# SN32F240 register map
Vendor: SONiX Technology Co., Ltd.; Series: SN32F200; File version: 2.0
CPU: CM0 r0p0, little endian, no MPU, no FPU, 2 interrupt priority bits
Registers are 32-bit, read-write, reset 0x0 unless marked. A register's access mark holds for its fields unless they carry their own. Offsets are from the block's base; [hi:lo] are bit positions; {n}, {i} and the like mark numbered series; 'fields as' and 'values as' point back to an identical list.

## SN_SYS1 — System Control Registers
Base 0x4005E000
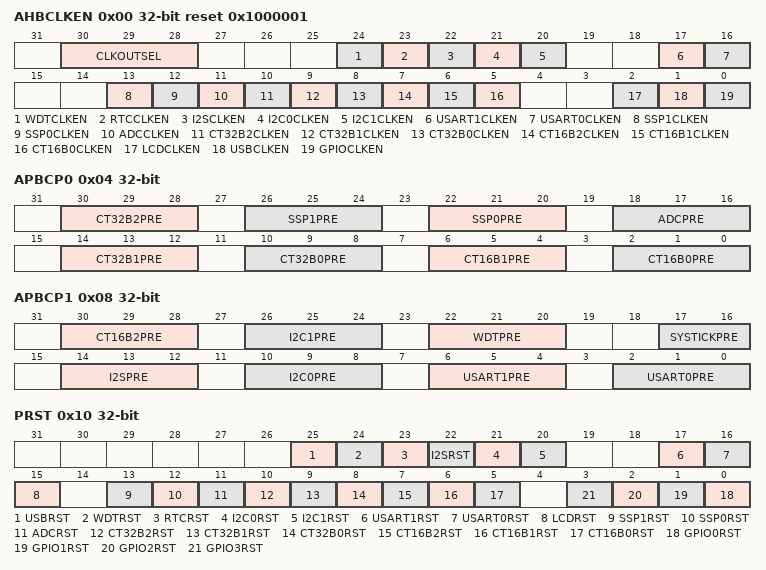
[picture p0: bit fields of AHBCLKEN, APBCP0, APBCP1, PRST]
0x00 AHBCLKEN reset 0x1000001 — Offset:0x00 AHB Clock Enable Register
  [30:28] CLKOUTSEL — Clock output source selection
    0=000b (Disable); 1=001b (ILRC); 2=010b (ELS XTAL); 4=100b (HCLK); 5=101b (IHRC); 6=110b (EHS XTAL); 7=111b (PLL output)
  [24] WDTCLKEN — Enable AHB clock for WDT
    0=Disable; 1=Enable
  [23] RTCCLKEN — Enable AHB clock for RTC
    0=Disable; 1=Enable
  [22] I2SCLKEN — Enable AHB clock for I2S
    0=Disable; 1=Enable
  [21] I2C0CLKEN — Enable AHB clock for I2C0
    0=Disable; 1=Enable
  [20] I2C1CLKEN — Enable AHB clock for I2C1
    0=Disable; 1=Enable
  [17] USART1CLKEN — Enable AHB clock for USART1
    0=Disable; 1=Enable
  [16] USART0CLKEN — Enable AHB clock for USART0
    0=Disable; 1=Enable
  [13] SSP1CLKEN — Enable AHB clock for SSP1
    0=Disable; 1=Enable
  [12] SSP0CLKEN — Enable AHB clock for SSP0
    0=Disable; 1=Enable
  [11] ADCCLKEN — Enable AHB clock for ADC
    0=Disable; 1=Enable
  [10] CT32B2CLKEN — Enable AHB clock for CT32B2
    0=Disable; 1=Enable
  [9] CT32B1CLKEN — Enable AHB clock for CT32B1
    0=Disable; 1=Enable
  [8] CT32B0CLKEN — Enable AHB clock for CT32B0
    0=Disable; 1=Enable
  [7] CT16B2CLKEN — Enable AHB clock for CT16B2
    0=Disable; 1=Enable
  [6] CT16B1CLKEN — Enable AHB clock for CT16B1
    0=Disable; 1=Enable
  [5] CT16B0CLKEN — Enable AHB clock for CT16B0
    0=Disable; 1=Enable
  [2] LCDCLKEN — Enable AHB clock for LCD
    0=Disable; 1=Enable
  [1] USBCLKEN — Enable AHB clock for USB
    0=Disable; 1=Enable
  [0] GPIOCLKEN — Enable AHB clock for GPIO
    0=Disable; 1=Enable
0x04 APBCP0 — Offset:0x04 APB Clock Prescale Register 0
  [all] fields
    0=000b (HCLK/1); 1=001b (HCLK/2); 2=010b (HCLK/4); 3=011b (HCLK/8); 4=100b (HCLK/16)
  [30:28] CT32B2PRE — CT32B2 APB clock source prescaler
  [26:24] SSP1PRE — SSP1 APB clock source prescaler
  [22:20] SSP0PRE — SSP0 APB clock source prescaler
  [18:16] ADCPRE — ADC APB clock source prescaler
  [14:12] CT32B1PRE — CT32B1 APB clock source prescaler
  [10:8] CT32B0PRE — CT32B0 APB clock source prescaler
  [6:4] CT16B1PRE — CT16B1 APB clock source prescaler
  [2:0] CT16B0PRE — CT16B0 APB clock source prescaler
0x08 APBCP1 — Offset:0x08 APB Clock Prescale Register 1
  [30:28] CT16B2PRE — CT16B2 APB clock source prescaler
    values as the fields of APBCP0
  [26:24] I2C1PRE — I2C1 APB clock source prescaler
    values as the fields of APBCP0
  [22:20] WDTPRE — WDT APB clock source prescaler
    0=000b (HCLK/1); 1=001b (HCLK/2); 2=010b (HCLK/4); 3=011b (HCLK/8); 4=100b (HCLK/16); 5=101b (HCLK/32)
  [17:16] SYSTICKPRE — SysTick APB clock source prescaler
    0=HCLK/1; 1=HCLK/2; 2=HCLK/4; 3=HCLK/8
  [14:12] I2SPRE — I2S APB clock source prescaler
    0=000b (HCLK/1); 1=001b (HCLK/2); 2=010b (HCLK/4); 3=011b (HCLK/8); 4=100b (HCLK/16); 7=111b (HCLK/3)
  [10:8] I2C0PRE — I2C0 APB clock source prescaler
    values as the fields of APBCP0
  [6:4] USART1PRE — USART1 APB clock source prescaler
    values as the fields of APBCP0
  [2:0] USART0PRE — USART0 APB clock source prescaler
    values as the fields of APBCP0
0x0C APBCP2 — Offset:0x0C APB Clock Prescale Register 2
  [3:0] CLKOUTPRE — CLKOUT APB clock source prescaler
    0=0000b (FCLKOUT/1); 1=0001b (FCLKOUT/2); 2=0010b (FCLKOUT/4); 3=0011b (FCLKOUT/8); 4=0100b (FCLKOUT/16); 5=0101b (FCLKOUT/32); 6=0110b (FCLKOUT/64); 7=0111b (FCLKOUT/128); 8=1000b (FCLKOUT/256); 9=1001b (FCLKOUT/512)
0x10 PRST (reset mask 0x3F33BCF) — Offset:0x10 Peripheral Reset Register
  [25] USBRST — USB Reset
    0=No effect; 1=Reset USB
  [24] WDTRST — WDT Reset
    0=No effect; 1=Reset WDT
  [23] RTCRST — RTC Reset
    0=No effect; 1=Reset RTC
  [22] I2SRST — I2S Reset
    0=No effect; 1=Reset I2S
  [21] I2C0RST — I2C0 Reset
    0=No effect; 1=Reset I2C0
  [20] I2C1RST — I2C1 Reset
    0=No effect; 1=Reset I2C1
  [17] USART1RST — USART1 Reset
    0=No effect; 1=Reset USART1
  [16] USART0RST — USART0 Reset
    0=No effect; 1=Reset USART0
  [15] LCDRST — LCD Reset
    0=No effect; 1=Reset LCD
  [13] SSP1RST — SSP1 Reset
    0=No effect; 1=Reset SSP1
  [12] SSP0RST — SSP0 Reset
    0=No effect; 1=Reset SSP0
  [11] ADCRST — ADC Reset
    0=No effect; 1=Reset ADC
  [10] CT32B2RST — CT32B2 Reset
    0=No effect; 1=Reset CT32B2
  [9] CT32B1RST — CT32B1 Reset
    0=No effect; 1=Reset CT32B1
  [8] CT32B0RST — CT32B0 Reset
    0=No effect; 1=Reset CT32B0
  [7] CT16B2RST — CT16B2 Reset
    0=No effect; 1=Reset CT16B2
  [6] CT16B1RST — CT16B1 Reset
    0=No effect; 1=Reset CT16B1
  [5] CT16B0RST — CT16B0 Reset
    0=No effect; 1=Reset CT16B0
  [n] GPIO{n}RST (n=0..3) — GPIO{n} Reset
    0=No effect; 1=Reset GPIO{n}
0x20 DIVIDEND — Offset:0x20 Divider Dividend Register
0x24 DIVISOR — Offset:0x24 Divider Dividend Register
0x28 QUOTIENT ro — Offset:0x28 Divider Quotient Register
0x2C REMAINDER ro — Offset:0x2C Divider Remainder Register
0x30 DIVCTRL — Offset:0x30 Divider Control Register
  [0] DIVS — Divider start control bit
    0=Idle (Divider stops/finishes operation); 1=Start to execute Dividing
